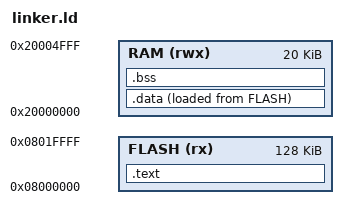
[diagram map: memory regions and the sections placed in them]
MEMORY
{
    FLASH (rx)  : ORIGIN = 0x08000000, LENGTH = 128K
    RAM   (rwx) : ORIGIN = 0x20000000, LENGTH = 20K
}

_estack = ORIGIN(RAM) + LENGTH(RAM);

SECTIONS
{
    .text :
    {
        . = ALIGN(4);
        KEEP(*(.isr_vector))
        *(.text*)
        *(.rodata*)
        . = ALIGN(4);
    } > FLASH

    .data :
    {
        . = ALIGN(4);
        *(.data*)
        . = ALIGN(4);
    } > RAM AT > FLASH

    .bss :
    {
        . = ALIGN(4);
        *(.bss*)
        *(COMMON)
        . = ALIGN(4);
    } > RAM
}
